AUTOSAR XML (schema 00050)
package /STLASWCs
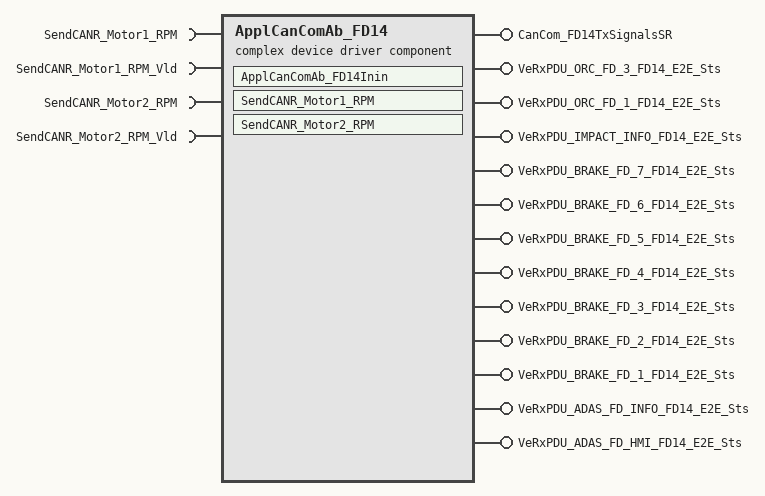
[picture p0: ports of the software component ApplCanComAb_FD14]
  complex device driver sw component type ApplCanComAb_FD14  # Application CAN Communication Abstraction Component - is responsible with receiving and sending CAN data from/to the lower BSW COM layers
    13 x provide port:
      CanCom_FD14TxSignalsSR: provided-interface=CanCom_FD14TxSignalsSR
        provided-com-specs:
          data-element=COMTX_Motor1_RPM_HYBRID_POWERTRAIN6_FD14, init-value=constant-reference=COMTX_Motor1_RPM_HYBRID_POWERTRAIN6_FD14_Init
          data-element=COMTX_Motor2_RPM_HYBRID_POWERTRAIN6_FD14, init-value=constant-reference=COMTX_Motor2_RPM_HYBRID_POWERTRAIN6_FD14_Init
      VeRxPDU_ORC_FD_3_FD14_E2E_Sts: provided-com-specs=[{data-element=E2ECheckSts, init-value=0}, {data-element=OpRetVal, init-value=0}], provided-interface=VeRxPDU_ORC_FD_3_FD14_E2E_Sts
      VeRxPDU_ORC_FD_1_FD14_E2E_Sts: provided-com-specs=[{data-element=E2ECheckSts, init-value=0}, {data-element=OpRetVal, init-value=0}], provided-interface=VeRxPDU_ORC_FD_1_FD14_E2E_Sts
      VeRxPDU_IMPACT_INFO_FD14_E2E_Sts: provided-com-specs=[{data-element=E2ECheckSts, init-value=0}, {data-element=OpRetVal, init-value=0}], provided-interface=VeRxPDU_IMPACT_INFO_FD14_E2E_Sts
      VeRxPDU_BRAKE_FD_7_FD14_E2E_Sts: provided-com-specs=[{data-element=E2ECheckSts, init-value=0}, {data-element=OpRetVal, init-value=0}], provided-interface=VeRxPDU_BRAKE_FD_7_FD14_E2E_Sts
      VeRxPDU_BRAKE_FD_6_FD14_E2E_Sts: provided-com-specs=[{data-element=E2ECheckSts, init-value=0}, {data-element=OpRetVal, init-value=0}], provided-interface=VeRxPDU_BRAKE_FD_6_FD14_E2E_Sts
      VeRxPDU_BRAKE_FD_5_FD14_E2E_Sts: provided-com-specs=[{data-element=E2ECheckSts, init-value=0}, {data-element=OpRetVal, init-value=0}], provided-interface=VeRxPDU_BRAKE_FD_5_FD14_E2E_Sts
      VeRxPDU_BRAKE_FD_4_FD14_E2E_Sts: provided-com-specs=[{data-element=E2ECheckSts, init-value=0}, {data-element=OpRetVal, init-value=0}], provided-interface=VeRxPDU_BRAKE_FD_4_FD14_E2E_Sts
      VeRxPDU_BRAKE_FD_3_FD14_E2E_Sts: provided-com-specs=[{data-element=E2ECheckSts, init-value=0}, {data-element=OpRetVal, init-value=0}], provided-interface=VeRxPDU_BRAKE_FD_3_FD14_E2E_Sts
      VeRxPDU_BRAKE_FD_2_FD14_E2E_Sts: provided-com-specs=[{data-element=E2ECheckSts, init-value=0}, {data-element=OpRetVal, init-value=0}], provided-interface=VeRxPDU_BRAKE_FD_2_FD14_E2E_Sts
      VeRxPDU_BRAKE_FD_1_FD14_E2E_Sts: provided-com-specs=[{data-element=E2ECheckSts, init-value=0}, {data-element=OpRetVal, init-value=0}], provided-interface=VeRxPDU_BRAKE_FD_1_FD14_E2E_Sts
      VeRxPDU_ADAS_FD_INFO_FD14_E2E_Sts: provided-com-specs=[{data-element=E2ECheckSts, init-value=0}, {data-element=OpRetVal, init-value=0}], provided-interface=VeRxPDU_ADAS_FD_INFO_FD14_E2E_Sts
      VeRxPDU_ADAS_FD_HMI_FD14_E2E_Sts: provided-com-specs=[{data-element=E2ECheckSts, init-value=0}, {data-element=OpRetVal, init-value=0}], provided-interface=VeRxPDU_ADAS_FD_HMI_FD14_E2E_Sts
    4 x require port:
      SendCANR_Motor1_RPM: nonqueued-receiver-com-spec{data-element=SendCANR_Motor1_RPM, init-value=SendCANR_Motor1_RPMValue:0}, required-interface=SendCANR_Motor1_RPM
      SendCANR_Motor1_RPM_Vld: nonqueued-receiver-com-spec{data-element=SendCANR_Motor1_RPM_Vld, init-value=SendCANR_Motor1_RPM_VldValue:1}, required-interface=SendCANR_Motor1_RPM_Vld
      SendCANR_Motor2_RPM: nonqueued-receiver-com-spec{data-element=SendCANR_Motor2_RPM, init-value=SendCANR_Motor2_RPMValue:0}, required-interface=SendCANR_Motor2_RPM
      SendCANR_Motor2_RPM_Vld: nonqueued-receiver-com-spec{data-element=SendCANR_Motor2_RPM_Vld, init-value=SendCANR_Motor2_RPM_VldValue:1}, required-interface=SendCANR_Motor2_RPM_Vld
    behavior IBApplCanComAb_FD14: data-type-mapping=ADTtoIDTMapping, handle-termination-and-restart=NO-SUPPORT
      init event IninEve: start-on-event=ApplCanComAb_FD14Inin
      data received event DRESendCANR_Motor1_RPM: start-on-event=SendCANR_Motor1_RPM, data=SendCANR_Motor1_RPM.SendCANR_Motor1_RPM
      data received event DRESendCANR_Motor2_RPM: start-on-event=SendCANR_Motor2_RPM, data=SendCANR_Motor2_RPM.SendCANR_Motor2_RPM
      runnable ApplCanComAb_FD14Inin: symbol=ApplCanComAb_FD14_ApplCanComAb_FD14Inin  # CAN SWC initialization runnable
        data-send-points:
          24 x access:
            DSP_VeRxPDU_ORC_FD_3_FD14_E2E_Sts_E2ECheckSts: accessed-variable=VeRxPDU_ORC_FD_3_FD14_E2E_Sts.E2ECheckSts
            DSP_VeRxPDU_ORC_FD_3_FD14_E2E_Sts_OpRetVal: accessed-variable=VeRxPDU_ORC_FD_3_FD14_E2E_Sts.OpRetVal
            DSP_VeRxPDU_ORC_FD_1_FD14_E2E_Sts_E2ECheckSts: accessed-variable=VeRxPDU_ORC_FD_1_FD14_E2E_Sts.E2ECheckSts
            DSP_VeRxPDU_ORC_FD_1_FD14_E2E_Sts_OpRetVal: accessed-variable=VeRxPDU_ORC_FD_1_FD14_E2E_Sts.OpRetVal
            DSP_VeRxPDU_IMPACT_INFO_FD14_E2E_Sts_E2ECheckSts: accessed-variable=VeRxPDU_IMPACT_INFO_FD14_E2E_Sts.E2ECheckSts
            DSP_VeRxPDU_IMPACT_INFO_FD14_E2E_Sts_OpRetVal: accessed-variable=VeRxPDU_IMPACT_INFO_FD14_E2E_Sts.OpRetVal
            DSP_VeRxPDU_BRAKE_FD_7_FD14_E2E_Sts_E2ECheckSts: accessed-variable=VeRxPDU_BRAKE_FD_7_FD14_E2E_Sts.E2ECheckSts
            DSP_VeRxPDU_BRAKE_FD_7_FD14_E2E_Sts_OpRetVal: accessed-variable=VeRxPDU_BRAKE_FD_7_FD14_E2E_Sts.OpRetVal
            DSP_VeRxPDU_BRAKE_FD_6_FD14_E2E_Sts_E2ECheckSts: accessed-variable=VeRxPDU_BRAKE_FD_6_FD14_E2E_Sts.E2ECheckSts
            DSP_VeRxPDU_BRAKE_FD_6_FD14_E2E_Sts_OpRetVal: accessed-variable=VeRxPDU_BRAKE_FD_6_FD14_E2E_Sts.OpRetVal
            DSP_VeRxPDU_BRAKE_FD_5_FD14_E2E_Sts_E2ECheckSts: accessed-variable=VeRxPDU_BRAKE_FD_5_FD14_E2E_Sts.E2ECheckSts
            DSP_VeRxPDU_BRAKE_FD_5_FD14_E2E_Sts_OpRetVal: accessed-variable=VeRxPDU_BRAKE_FD_5_FD14_E2E_Sts.OpRetVal
            DSP_VeRxPDU_BRAKE_FD_4_FD14_E2E_Sts_E2ECheckSts: accessed-variable=VeRxPDU_BRAKE_FD_4_FD14_E2E_Sts.E2ECheckSts
            DSP_VeRxPDU_BRAKE_FD_4_FD14_E2E_Sts_OpRetVal: accessed-variable=VeRxPDU_BRAKE_FD_4_FD14_E2E_Sts.OpRetVal
            DSP_VeRxPDU_BRAKE_FD_3_FD14_E2E_Sts_E2ECheckSts: accessed-variable=VeRxPDU_BRAKE_FD_3_FD14_E2E_Sts.E2ECheckSts
            DSP_VeRxPDU_BRAKE_FD_3_FD14_E2E_Sts_OpRetVal: accessed-variable=VeRxPDU_BRAKE_FD_3_FD14_E2E_Sts.OpRetVal
            DSP_VeRxPDU_BRAKE_FD_2_FD14_E2E_Sts_E2ECheckSts: accessed-variable=VeRxPDU_BRAKE_FD_2_FD14_E2E_Sts.E2ECheckSts
            DSP_VeRxPDU_BRAKE_FD_2_FD14_E2E_Sts_OpRetVal: accessed-variable=VeRxPDU_BRAKE_FD_2_FD14_E2E_Sts.OpRetVal
            DSP_VeRxPDU_BRAKE_FD_1_FD14_E2E_Sts_E2ECheckSts: accessed-variable=VeRxPDU_BRAKE_FD_1_FD14_E2E_Sts.E2ECheckSts
            DSP_VeRxPDU_BRAKE_FD_1_FD14_E2E_Sts_OpRetVal: accessed-variable=VeRxPDU_BRAKE_FD_1_FD14_E2E_Sts.OpRetVal
            DSP_VeRxPDU_ADAS_FD_INFO_FD14_E2E_Sts_E2ECheckSts: accessed-variable=VeRxPDU_ADAS_FD_INFO_FD14_E2E_Sts.E2ECheckSts
            DSP_VeRxPDU_ADAS_FD_INFO_FD14_E2E_Sts_OpRetVal: accessed-variable=VeRxPDU_ADAS_FD_INFO_FD14_E2E_Sts.OpRetVal
            DSP_VeRxPDU_ADAS_FD_HMI_FD14_E2E_Sts_E2ECheckSts: accessed-variable=VeRxPDU_ADAS_FD_HMI_FD14_E2E_Sts.E2ECheckSts
            DSP_VeRxPDU_ADAS_FD_HMI_FD14_E2E_Sts_OpRetVal: accessed-variable=VeRxPDU_ADAS_FD_HMI_FD14_E2E_Sts.OpRetVal
        5 x parameter access:
          SCPVA_KeCANR_b_ComTxMsg_AXLE_TORQUE_FD_1_FD14_Enbld: accessed-parameter=KeCANR_b_ComTxMsg_AXLE_TORQUE_FD_1_FD14_Enbld
          SCPVA_KeCANR_b_ComTxMsg_BATTERY_HV_STATUS1_FD14_Enbld: accessed-parameter=KeCANR_b_ComTxMsg_BATTERY_HV_STATUS1_FD14_Enbld
          SCPVA_KeCANR_b_ComTxMsg_HYBRID_POWERTRAIN6_FD14_Enbld: accessed-parameter=KeCANR_b_ComTxMsg_HYBRID_POWERTRAIN6_FD14_Enbld
          SCPVA_KeCANR_b_ComTxMsg_PT_SYSTEM_FD_1_FD14_Enbld: accessed-parameter=KeCANR_b_ComTxMsg_PT_SYSTEM_FD_1_FD14_Enbld
          SCPVA_KeCANR_b_ComTxMsg_PT_TORQUE_FD_1_FD14_Enbld: accessed-parameter=KeCANR_b_ComTxMsg_PT_TORQUE_FD_1_FD14_Enbld
      runnable SendCANR_Motor1_RPM: can-be-invoked-concurrently=true, symbol=ApplCanComAb_FD14_SendCANR_Motor1_RPM  # Transmit
        data-receive-point-by-arguments:
          access DRP_SendCANR_Motor1_RPM_SendCANR_Motor1_RPM: accessed-variable=SendCANR_Motor1_RPM.SendCANR_Motor1_RPM
          access DRP_SendCANR_Motor1_RPM_Vld_SendCANR_Motor1_RPM_Vld: accessed-variable=SendCANR_Motor1_RPM_Vld.SendCANR_Motor1_RPM_Vld
        data-send-points:
          access DSP_CanCom_FD14TxSignalsSR_COMTX_Motor1_RPM_HYBRID_POWERTRAIN6_FD14: accessed-variable=CanCom_FD14TxSignalsSR.COMTX_Motor1_RPM_HYBRID_POWERTRAIN6_FD14
      runnable SendCANR_Motor2_RPM: can-be-invoked-concurrently=true, symbol=ApplCanComAb_FD14_SendCANR_Motor2_RPM  # Transmit
        data-receive-point-by-arguments:
          access DRP_SendCANR_Motor2_RPM_SendCANR_Motor2_RPM: accessed-variable=SendCANR_Motor2_RPM.SendCANR_Motor2_RPM
          access DRP_SendCANR_Motor2_RPM_Vld_SendCANR_Motor2_RPM_Vld: accessed-variable=SendCANR_Motor2_RPM_Vld.SendCANR_Motor2_RPM_Vld
        data-send-points:
          access DSP_CanCom_FD14TxSignalsSR_COMTX_Motor2_RPM_HYBRID_POWERTRAIN6_FD14: accessed-variable=CanCom_FD14TxSignalsSR.COMTX_Motor2_RPM_HYBRID_POWERTRAIN6_FD14
      shared-parameters:
        5 x parameter data prototype, all with type=ADTSBoolean, init-value=1:
          KeCANR_b_ComTxMsg_AXLE_TORQUE_FD_1_FD14_Enbld
          KeCANR_b_ComTxMsg_BATTERY_HV_STATUS1_FD14_Enbld
          KeCANR_b_ComTxMsg_HYBRID_POWERTRAIN6_FD14_Enbld
          KeCANR_b_ComTxMsg_PT_SYSTEM_FD_1_FD14_Enbld
          KeCANR_b_ComTxMsg_PT_TORQUE_FD_1_FD14_Enbld
package /STLASWCs/ComSwCpts/ComDataDefinition/ComConstSpec
  constant specification COMTX_Motor1_RPM_HYBRID_POWERTRAIN6_FD14_Init: value-spec=32768
  constant specification COMTX_Motor2_RPM_HYBRID_POWERTRAIN6_FD14_Init: value-spec=32768
package /STLASWCs/ComSwCpts/ComDataDefinition/ComImpDataType
  impl type IDTSMotor1_RPM_HYBRID_POWERTRAIN6_FD14: implementation-data-type=uint16
  impl type IDTSMotor2_RPM_HYBRID_POWERTRAIN6_FD14: implementation-data-type=uint16
package /STLASWCs/ComSwCpts/ComPrivateInterfaces
  sender receiver interface CanCom_FD14TxSignalsSR
    data COMTX_Motor1_RPM_HYBRID_POWERTRAIN6_FD14: category=TYPE_REFERENCE, sw-calibration-access=READ-ONLY, type=IDTSMotor1_RPM_HYBRID_POWERTRAIN6_FD14, init-value=COMTX_Motor1_RPM_HYBRID_POWERTRAIN6_FD14Value:32768  # Raw signal data to be transmitted over the CAN bus for the Signal Motor1_RPM
    data COMTX_Motor2_RPM_HYBRID_POWERTRAIN6_FD14: category=TYPE_REFERENCE, sw-calibration-access=READ-ONLY, type=IDTSMotor2_RPM_HYBRID_POWERTRAIN6_FD14, init-value=COMTX_Motor2_RPM_HYBRID_POWERTRAIN6_FD14Value:32768  # Raw signal data to be transmitted over the CAN bus for the Signal Motor2_RPM
    invalidation-policys:
      data-element=COMTX_Motor1_RPM_HYBRID_POWERTRAIN6_FD14, handle-invalid=DONT-INVALIDATE
      data-element=COMTX_Motor2_RPM_HYBRID_POWERTRAIN6_FD14, handle-invalid=DONT-INVALIDATE
